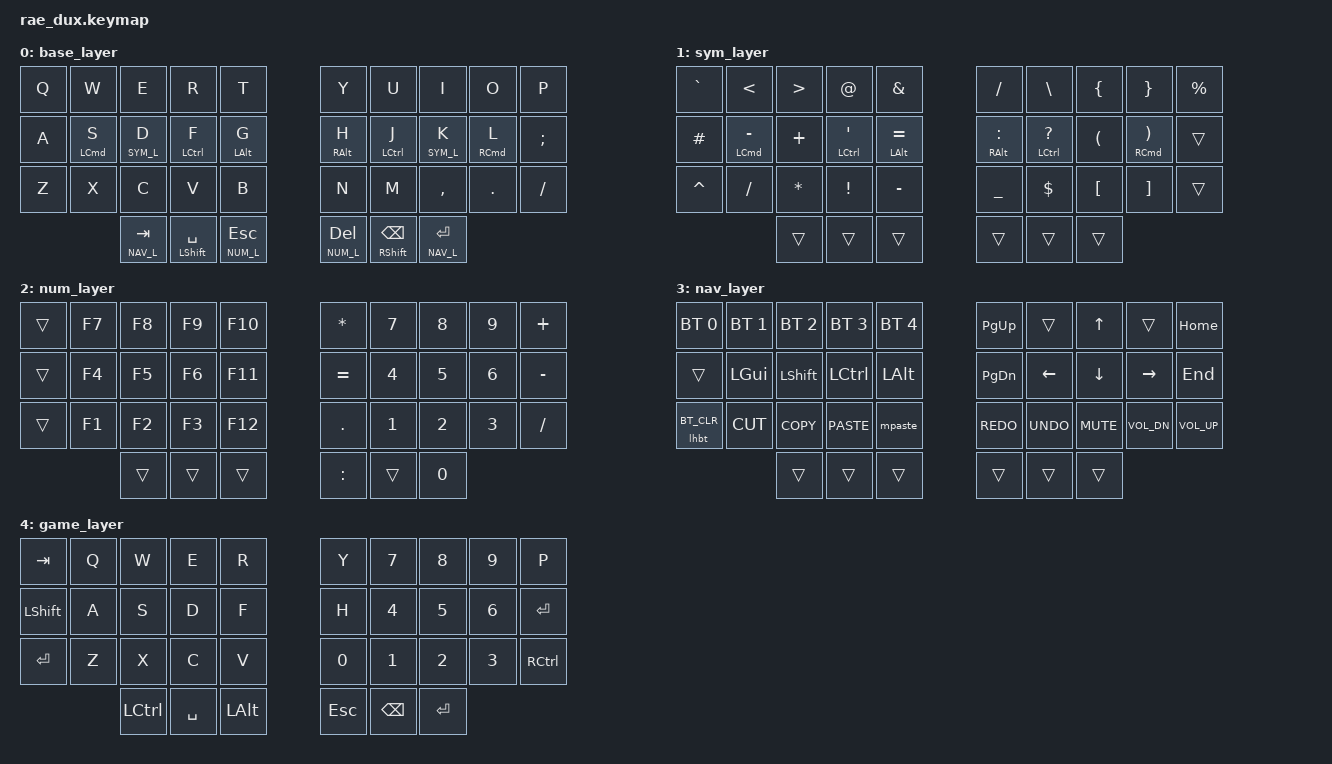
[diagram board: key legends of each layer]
/*
 * Copyright (c) 2021 The ZMK Contributors
 *
 * SPDX-License-Identifier: MIT
 */

#include <behaviors.dtsi>
#include <dt-bindings/zmk/bt.h>
#include <dt-bindings/zmk/keys.h>

&sk {
    release-after-ms = <750>;
    quick-release;
};

&caps_word {
    continue-list = <UNDERSCORE MINUS BSPC>;
};

#define BASE_L  0
#define SYM_L   1
#define NUM_L   2
#define NAV_L   3
#define GAME_L  4

#define CUT    LG(X)
#define COPY   LG(C)
#define PASTE  LG(V)

#define UNDO LG(Z)
#define REDO LS(LG(Z))

#define MEH(KEY) LS(LC(LA(LG(KEY))))

/ {
    macros {
        ZMK_MACRO(mpaste, 
            bindings = 
                <&macro_press &kp LSHFT>,
                <&macro_tap &sk LCMD &kp V>,
                <&macro_pause_for_release>,
                <&macro_release &kp LSHFT>
            ;)
    };

    combos {
        compatible = "zmk,combos";

        #define COMBO(NAME, BINDINGS, KEYPOS, TIMEOUT) \
              combo_##NAME { \
                timeout-ms = <TIMEOUT>; \
                bindings = <BINDINGS>; \
                key-positions = <KEYPOS>; \
              };

        /*                KEY POSITIONS

          ╭────────────────────╮ ╭────────────────────╮
          │  0   1   2   3   4 │ │  5   6   7   8   9 │
          │ 10  11  12  13  14 │ │ 15  16  17  18  19 │
          │ 20  21  22  23  24 │ │ 25  26  27  28  29 │
          ╰───────╮ 30  31  32 │ │ 33  34  35 ╭───────╯
                  ╰────────────╯ ╰────────────╯        */

        // COMBO(caps_word_left, &caps_word, 13 14, 60)
        // COMBO(caps_word_right, &caps_word, 15 16, 60)

        // COMBO(grave, &kp GRAVE, 1 2, 60)
        // COMBO(colon, &kp COLON, 7 8, 60)
        // COMBO(equal, &kp EQUAL, 21 22, 60)
        // COMBO(semicolon, &kp SEMI, 27 28, 60)

        // COMBO(minus, &kp MINUS, 31 34, 60)
        // COMBO(underscore, &kp UNDER, 32 33, 60)

        COMBO(gaming, &tog GAME_L, 30 31 32 33 34 35, 60)
    };

    behaviors {
        lhm: left_hand_positional_hold_tap {
            compatible = "zmk,behavior-hold-tap";
            label = "LEFT_POSITIONAL_HOLD_TAP";
            #binding-cells = <2>;
            flavor = "tap-preferred";
            tapping-term-ms = <200>;
            quick-tap-ms = <200>;
            require-prior-idle-ms = <50>;
            bindings = <&kp>, <&kp>;
            // hold-trigger-key-positions = <5 6 7 8 9 10 11 12 13 14 15 16 17 18 19 25 26 27 28 29 30 31 32 33 34 35>;
        };

        rhm: right_hand_positional_hold_tap {
            compatible = "zmk,behavior-hold-tap";
            label = "RIGHT_POSITIONAL_HOLD_TAP";
            #binding-cells = <2>;
            flavor = "tap-preferred";
            tapping-term-ms = <200>;
            quick-tap-ms = <200>;
            require-prior-idle-ms = <50>;
            bindings = <&kp>, <&kp>;
            // hold-trigger-key-positions = <0 1 2 3 4 10 11 12 13 14 16 17 18 19 20 21 22 23 24 30 31 32 33 34 35>;
        };

        mts: mod_tap_space {
            compatible = "zmk,behavior-hold-tap";
            label = "MOD_TAP_SPACE";
            #binding-cells = <2>;
            flavor = "tap-preferred";
            tapping-term-ms = <200>;
            quick-tap-ms = <200>;
            bindings = <&kp>, <&kp>;
        };

        blt: base_layer_hold_tap {
            compatible = "zmk,behavior-hold-tap";
            label = "BASE_LAYER_HOLD_TAP";
            #binding-cells = <2>;
            flavor = "tap-preferred";
            tapping-term-ms = <200>;
            quick-tap-ms = <200>;
            require-prior-idle-ms = <100>;
            bindings = <&mo>, <&kp>;
        };

        rpt_lt: repeat_hold_tap {
            compatible = "zmk,behavior-hold-tap";
            label = "REPEAT_HOLD_TAP";
            #binding-cells = <2>;
            flavor = "tap-preferred";
            tapping-term-ms = <200>;
            quick-tap-ms = <200>;
            global-quick-tap;
            bindings = <&mo>, <&key_repeat>;
        };

        lhbt: long_hold_bluetooth {
            compatible = "zmk,behavior-hold-tap";
            label = "LONG_HOLD";
            #binding-cells = <2>;
            flavor = "tap-preferred";
            tapping-term-ms = <1000>;
            bindings = <&bt>, <&trans>;
        };
    };

	keymap {
		compatible = "zmk,keymap";

		/*&                                                                                 |                                                                                  &*/
        base_layer {
			bindings = <
                   &kp Q        &kp W         &kp E              &kp R              &kp T              &kp Y              &kp U               &kp I                 &kp O         &kp P
                   &kp A        &lhm LCMD S   &blt SYM_L D       &lhm LCTRL F       &lhm LALT G        &rhm RALT H        &rhm LCTRL J        &blt SYM_L K          &rhm RCMD L   &kp SEMICOLON
                   &kp Z        &kp X         &kp C              &kp V              &kp B              &kp N              &kp M               &kp COMMA             &kp DOT       &kp FSLH
				 /*&            &*/           &blt NAV_L TAB     &mts LSHFT SPC     &blt NUM_L ESC     &blt NUM_L DEL     &mts RSHFT BSPC     &blt NAV_L RET   /*&             &*/
			>;
		};

        /*&                                                                                        |                                                                                  &*/
		sym_layer {
			bindings = <
                   &kp GRAVE    &kp LT          &kp GT            &kp AT             &kp AMPS           &kp FSLH            &kp BSLH         &kp LBRC               &kp RBRC       &kp PRCNT
                   &kp HASH     &lhm LCMD MINUS &kp PLUS          &lhm LCTRL APOS    &lhm LALT EQUAL    &rhm RALT COLON     &rhm LCTRL QMARK &kp LPAR               &rhm RCMD RPAR &trans
                   &kp CARET    &kp FSLH        &kp STAR          &kp EXCL           &kp MINUS          &kp UNDERSCORE      &kp DLLR         &kp LBKT               &kp RBKT       &trans
				 /*&            &*/             &trans            &trans             &trans             &trans              &trans           &trans         /*&             &*/
			>;
		};

		num_layer {
			bindings = <
                   &trans       &kp F7        &kp F8        &kp F9             &kp F10            &kp STAR            &kp N7           &kp N8                   &kp N9        &kp PLUS
                   &trans       &kp F4        &kp F5        &kp F6             &kp F11            &kp EQUAL           &kp N4           &kp N5                   &kp N6        &kp MINUS
                   &trans       &kp F1        &kp F2        &kp F3             &kp F12            &kp DOT             &kp N1           &kp N2                   &kp N3        &kp FSLH
				 /*&            &*/           &trans        &trans             &trans             &kp COLON           &trans           &kp N0                 /*&             &*/
			>;
		};

		nav_layer {
			bindings =  <
                   &bt BT_SEL 0 &bt BT_SEL 1  &bt BT_SEL 2  &bt BT_SEL 3       &bt BT_SEL 4       &kp PG_UP           &trans           &kp UP                   &trans        &kp HOME
                   &trans       &kp LGUI      &kp LSHFT     &kp LCTRL          &kp LALT           &kp PG_DN           &kp LEFT         &kp DOWN                 &kp RIGHT     &kp END
                   &lhbt BT_CLR &kp CUT       &kp COPY      &kp PASTE          &mpaste            &kp REDO            &kp UNDO         &kp C_MUTE               &kp C_VOL_DN  &kp C_VOL_UP
				 /*&            &*/           &trans        &trans             &trans             &trans              &trans           &trans                 /*&             &*/
			>;
		};

        // still need ctrl + alt on left hand
        game_layer {
			bindings =  <
                   &kp TAB      &kp Q         &kp W         &kp E              &kp R              &kp Y              &kp N7              &kp N8               &kp N9         &kp P
                   &kp LSHIFT   &kp A         &kp S         &kp D              &kp F              &kp H              &kp N4              &kp N5               &kp N6         &kp RET
                   &kp RET      &kp Z         &kp X         &kp C              &kp V              &kp N0             &kp N1              &kp N2               &kp N3         &kp RCTRL
				 /*&            &*/           &kp LCTRL     &kp SPC            &kp LALT           &kp ESC            &kp BSPC            &kp RET             /*&             &*/
            >;
		};
	};
};
